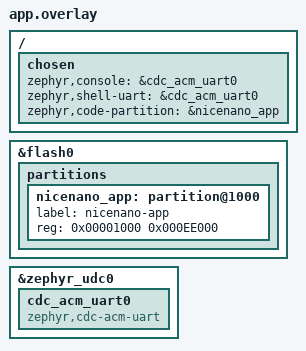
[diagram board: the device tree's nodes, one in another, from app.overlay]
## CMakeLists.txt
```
cmake_minimum_required(VERSION 3.20.0)
find_package(Zephyr REQUIRED HINTS $ENV{ZEPHYR_BASE})
project(nrf52840_nicenano_usb_cdc_banner)
target_sources(app PRIVATE src/main.c ../nrf52840_nicenano_common/ael_usb.c)
```

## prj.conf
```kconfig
# nice!nano USB CDC banner — Stage 0 serial health check
# Prints "AEL_READY nRF52840" over USB CDC every 500 ms.

CONFIG_GPIO=y
CONFIG_SERIAL=y
CONFIG_CONSOLE=y
CONFIG_UART_CONSOLE=y
CONFIG_STDOUT_CONSOLE=y
CONFIG_PRINTK=y

# USB CDC-ACM console (new stack)
CONFIG_USB_DEVICE_STACK_NEXT=y
CONFIG_USBD_CDC_ACM_CLASS=y
CONFIG_UART_LINE_CTRL=y
CONFIG_HWINFO=y

# UF2 output
CONFIG_BUILD_OUTPUT_UF2=y
CONFIG_BUILD_OUTPUT_UF2_FAMILY_ID="0x239A00B3"
CONFIG_FLASH_LOAD_OFFSET=0x1000
CONFIG_FLASH_LOAD_SIZE=0xEE000
```

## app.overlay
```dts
/*
 * nice!nano USB CDC banner overlay
 * - Routes console to USB CDC (cdc_acm_uart0)
 * - Sets code partition at 0x1000 (Adafruit UF2 bootloader)
 */

/ {
    chosen {
        zephyr,console = &cdc_acm_uart0;
        zephyr,shell-uart = &cdc_acm_uart0;
        zephyr,code-partition = &nicenano_app;
    };
};

&flash0 {
    partitions {
        nicenano_app: partition@1000 {
            label = "nicenano-app";
            reg = <0x00001000 0x000EE000>;
        };
    };
};

&zephyr_udc0 {
    cdc_acm_uart0: cdc_acm_uart0 {
        compatible = "zephyr,cdc-acm-uart";
    };
};
```

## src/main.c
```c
/*
 * AEL Stage 0 — nRF52840 nice!nano USB CDC banner
 *
 * Prints "AEL_READY nRF52840 count=N" over USB CDC every 500 ms.
 * Supports 1200-baud bootloader re-entry via ael_usb.h.
 */

#include <zephyr/kernel.h>
#include <zephyr/sys/printk.h>
#include "../../nrf52840_nicenano_common/ael_usb.h"

int main(void)
{
    ael_usb_init();
    k_msleep(1500);

    uint32_t count = 0;
    while (1) {
        if (atomic_get(&ael_bl_flag)) { k_msleep(50); ael_enter_bootloader(); }
        printk("AEL_READY nRF52840 count=%u\n", count++);
        k_msleep(500);
    }
    return 0;
}
```
